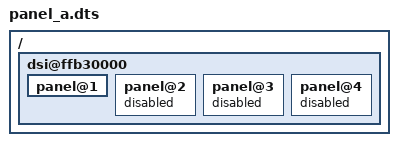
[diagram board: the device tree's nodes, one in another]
/dts-v1/;

/include/ "00.00.28.36.dts"

/ {
	dsi@ffb30000 {
		panel@1 {
			status = "okay";
		};
		panel@2 {
			status = "disabled";
		};
		panel@3 {
			status = "disabled";
		};
		panel@4 {
			status = "disabled";
		};
	};
};

